# MIMXRT1052 register map
Vendor: nxp.com; File version: 1.0
CPU: CM7 r0p1, little endian, MPU, FPU, VTOR, 4 interrupt priority bits
Registers are 32-bit, read-write, reset 0x0 unless marked. A register's access mark holds for its fields unless they carry their own. Offsets are from the block's base; [hi:lo] are bit positions; {n}, {i} and the like mark numbered series; 'fields as' and 'values as' point back to an identical list.

## ADC_ETC
Base 0x403B0000
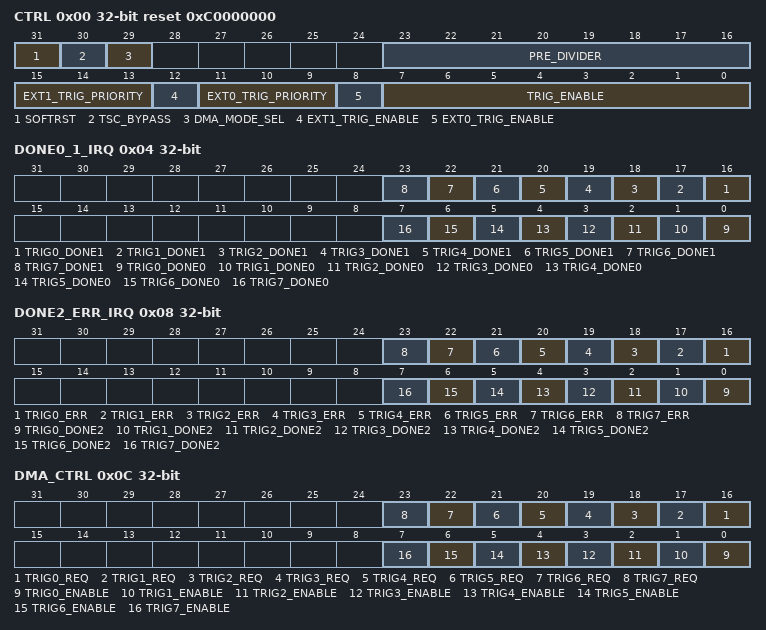
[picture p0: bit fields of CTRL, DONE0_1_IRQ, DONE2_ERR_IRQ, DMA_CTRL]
0x00 CTRL reset 0xC0000000 — ADC_ETC Global Control Register
  [31] SOFTRST — Software reset, high active. When write 1 ,all logical will be reset.
  [30] TSC_BYPASS — 1'b1: TSC is bypassed to ADC2. 1'b0: TSC not bypassed. To use ADC2, this bit should be cleared.
  [29] DMA_MODE_SEL — 1'b0: Trig DMA_REQ with latched signal, REQ will be cleared when ACK and source request cleared
  [23:16] PRE_DIVIDER — Pre-divider for trig delay and interval .
  [15:13] EXT1_TRIG_PRIORITY — External TSC1 trigger priority, 7 is Highest, 0 is lowest .
  [12] EXT1_TRIG_ENABLE — TSC1 TRIG enable register. 1'b1: enable external TSC1 trigger. 1'b0: disable external TSC1 trigger.
  [11:9] EXT0_TRIG_PRIORITY — External TSC0 trigger priority, 7 is Highest, 0 is lowest .
  [8] EXT0_TRIG_ENABLE — TSC0 TRIG enable register. 1'b1: enable external TSC0 trigger. 1'b0: disable external TSC0 trigger.
  [7:0] TRIG_ENABLE
0x04 DONE0_1_IRQ — ETC DONE0 and DONE1 IRQ State Register
  [n+16] TRIG{n}_DONE1 (n=0..7) — TRIG{n} done1 interrupt detection
  [n] TRIG{n}_DONE0 (n=0..7) — TRIG{n} done0 interrupt detection
0x08 DONE2_ERR_IRQ — ETC DONE_2 and DONE_ERR IRQ State Register
  [n+16] TRIG{n}_ERR (n=0..7) — TRIG{n} error interrupt detection
  [n] TRIG{n}_DONE2 (n=0..7) — TRIG{n} done2 interrupt detection
0x0C DMA_CTRL — ETC DMA control Register
  [n+16] TRIG{n}_REQ (n=0..7) — When TRIG{n} done DMA request detection
  [n] TRIG{n}_ENABLE (n=0..7) — When TRIG{n} done enable DMA request
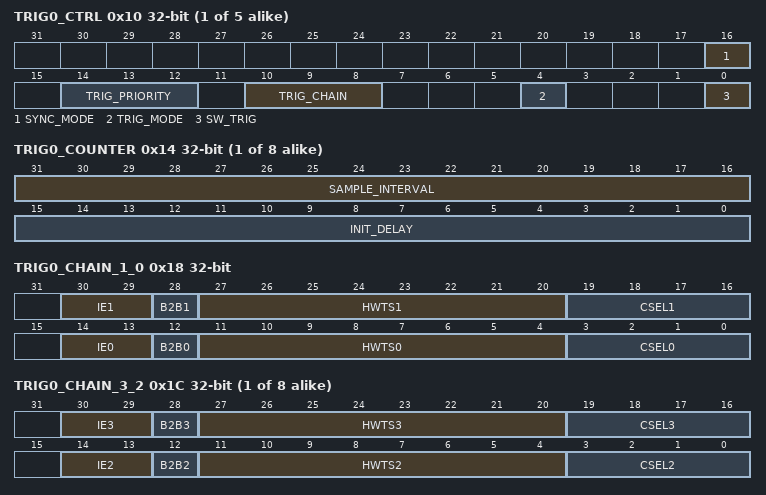
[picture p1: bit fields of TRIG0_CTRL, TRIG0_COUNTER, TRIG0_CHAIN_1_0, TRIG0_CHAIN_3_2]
{0x10+0x28*i} TRIG{i}_CTRL (i=0..4) — ETC_TRIG{i} Control Register
  [16] SYNC_MODE — TRIG mode control . 1'b0: Disable sync mode; 1'b1: Enable sync mode
  [14:12] TRIG_PRIORITY — External trigger priority, 7 is highest, 0 is lowest .
  [10:8] TRIG_CHAIN — TRIG chain length to the ADC. 0: Trig length is 1; ... 7: Trig length is 8;
  [4] TRIG_MODE — TRIG mode register. 1'b0: hardware trigger. 1'b1: software trigger.
  [0] SW_TRIG — Software write 1 as the TRIGGER. This register is self-clearing.
{0x14+0x28*i} TRIG{i}_COUNTER (i=0..7) — ETC_TRIG{i} Counter Register
  [31:16] SAMPLE_INTERVAL — TRIGGER sampling interval counter
  [15:0] INIT_DELAY — TRIGGER initial delay counter
0x18 TRIG0_CHAIN_1_0 — ETC_TRIG Chain 0/1 Register
  [30:29] IE1 — CHAIN1 IE 2'b00: No interrupt when finished 2'b01: Finished Interrupt on Done0 2'b10: Finished Interrupt on Done1 2'b11: Finished Interrupt on Done2
  [28] B2B1 — CHAIN1 B2B 1'b0: Disable B2B, wait until interval is reached 1'b1: Enable B2B, back to back ADC trigger
  [27:20] HWTS1 — CHAIN1 HWTS ADC hardware trigger selection. For more information, see the ADC chapter.
  [19:16] CSEL1 — CHAIN1 CSEL ADC channel selection
  [14:13] IE0 — CHAIN0 IE 2'b00: No interrupt when finished 2'b01: Finished Interrupt on Done0 2'b10: Finished Interrupt on Done1 2'b11: Finished Interrupt on Done2
  [12] B2B0 — CHAIN0 B2B 1'b0: Disable B2B, wait until interval is reached 1'b1: Enable B2B, back to back ADC trigger
  [11:4] HWTS0 — CHAIN0 HWTS ADC hardware trigger selection. For more information, see the ADC chapter.
  [3:0] CSEL0 — CHAIN0 CSEL ADC channel selection
{0x1C+0x28*i} TRIG{i}_CHAIN_3_2 (i=0..7) — ETC_TRIG Chain 2/3 Register
  [30:29] IE3 — CHAIN3 IE
  [28] B2B3 — CHAIN3 B2B
  [27:20] HWTS3 — CHAIN3 HWTS
  [19:16] CSEL3 — CHAIN3 CSEL
  [14:13] IE2 — CHAIN2 IE
  [12] B2B2 — CHAIN2 B2B
  [11:4] HWTS2 — CHAIN2 HWTS
  [3:0] CSEL2 — CHAIN2 CSEL
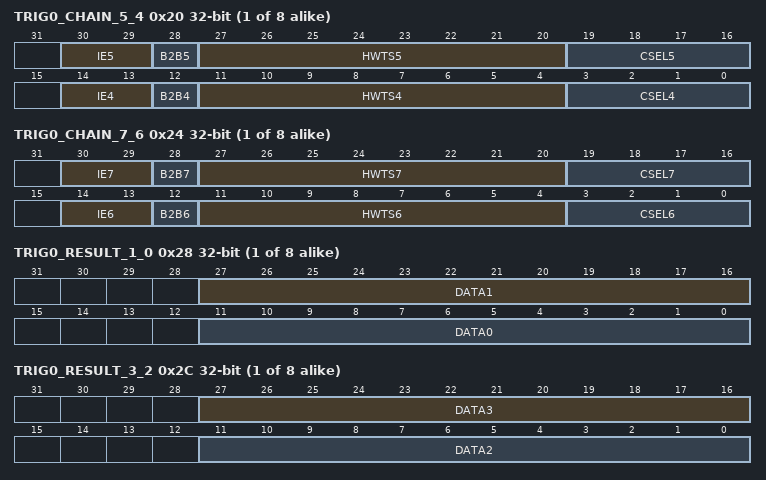
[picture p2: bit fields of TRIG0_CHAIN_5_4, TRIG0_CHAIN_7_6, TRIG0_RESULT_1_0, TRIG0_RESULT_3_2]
{0x20+0x28*i} TRIG{i}_CHAIN_5_4 (i=0..7) — ETC_TRIG Chain 4/5 Register
  [30:29] IE5 — CHAIN5 IE
  [28] B2B5 — CHAIN5 B2B
  [27:20] HWTS5 — CHAIN5 HWTS
  [19:16] CSEL5 — CHAIN5 CSEL
  [14:13] IE4 — CHAIN4 IE
  [12] B2B4 — CHAIN4 B2B
  [11:4] HWTS4 — CHAIN4 HWTS
  [3:0] CSEL4 — CHAIN4 CSEL
{0x24+0x28*i} TRIG{i}_CHAIN_7_6 (i=0..7) — ETC_TRIG Chain 6/7 Register
  [30:29] IE7 — CHAIN7 IE
  [28] B2B7 — CHAIN7 B2B
  [27:20] HWTS7 — CHAIN7 HWTS
  [19:16] CSEL7 — CHAIN7 CSEL
  [14:13] IE6 — CHAIN6 IE
  [12] B2B6 — CHAIN6 B2B
  [11:4] HWTS6 — CHAIN6 HWTS
  [3:0] CSEL6 — CHAIN6 CSEL
{0x28+0x28*i} TRIG{i}_RESULT_1_0 ro (i=0..7) — ETC_TRIG Result Data 1/0 Register
  [27:16] DATA1 — Result DATA1
  [11:0] DATA0 — Result DATA0
{0x2C+0x28*i} TRIG{i}_RESULT_3_2 ro (i=0..7) — ETC_TRIG Result Data 3/2 Register
  [27:16] DATA3 — Result DATA3
  [11:0] DATA2 — Result DATA2
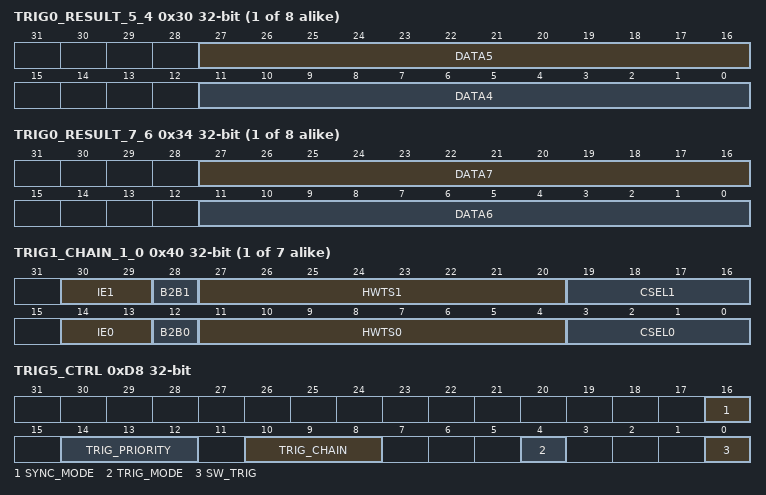
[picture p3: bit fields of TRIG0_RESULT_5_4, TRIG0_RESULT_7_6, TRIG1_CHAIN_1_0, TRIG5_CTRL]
{0x30+0x28*i} TRIG{i}_RESULT_5_4 ro (i=0..7) — ETC_TRIG Result Data 5/4 Register
  [27:16] DATA5 — Result DATA5
  [11:0] DATA4 — Result DATA4
{0x34+0x28*i} TRIG{i}_RESULT_7_6 ro (i=0..7) — ETC_TRIG Result Data 7/6 Register
  [27:16] DATA7 — Result DATA7
  [11:0] DATA6 — Result DATA6
{0x18+0x28*i} TRIG{i}_CHAIN_1_0 (i=1..7) — ETC_TRIG Chain 0/1 Register
  [30:29] IE1 — CHAIN1 IE 2'b00: No interrupt when finished 2'b01: Finished Interrupt on Done0 2'b10: Finished Interrupt on Done1 2'b11: Finished Interrupt on Done2
  [28] B2B1 — CHAIN1 B2B 1'b0: Disable B2B, wait until interval is reached 1'b1: Enable B2B, back to back ADC trigger
  [27:20] HWTS1 — CHAIN1 HWTS ADC hardware trigger selection
  [19:16] CSEL1 — CHAIN1 CSEL ADC channel selection
  [14:13] IE0 — CHAIN0 IE 2'b00: No interrupt when finished 2'b01: Finished Interrupt on Done0 2'b10: Finished Interrupt on Done1 2'b11: Finished Interrupt on Done2
  [12] B2B0 — CHAIN0 B2B 1'b0: Disable B2B, wait until interval is reached 1'b1: Enable B2B, back to back ADC trigger
  [11:4] HWTS0 — CHAIN0 HWTS ADC hardware trigger selection
  [3:0] CSEL0 — CHAIN0 CSEL ADC channel selection
0xD8 TRIG5_CTRL — ETC_TRIG5 Control Register
  [16] SYNC_MODE — TRIG mode control . 1'b0: Disable sync mode; 1'b1: Enable sync mode
  [14:12] TRIG_PRIORITY — External trigger priority, 7 is highest, 0 is lowest .
  [10:8] TRIG_CHAIN — TRIG chain length to the ADC. 0: Trig length is 1; ... 7: Trig length is 8;
  [4] TRIG_MODE — TRIG mode register. 1'b0: hardware trigger. 1'b1: software trigger.
  [0] SW_TRIG — Software write 1 as the TRIGGER
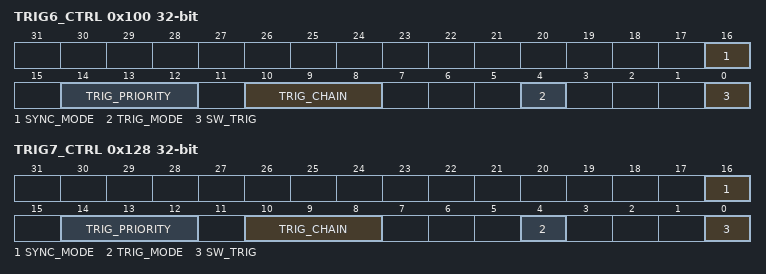
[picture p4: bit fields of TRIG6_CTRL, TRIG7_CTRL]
0x100 TRIG6_CTRL — ETC_TRIG6 Control Register
  fields as TRIG0_CTRL
0x128 TRIG7_CTRL — ETC_TRIG7 Control Register
  fields as TRIG0_CTRL
